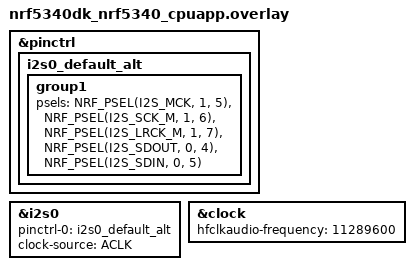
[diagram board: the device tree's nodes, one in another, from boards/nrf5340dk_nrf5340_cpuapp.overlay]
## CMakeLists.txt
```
cmake_minimum_required(VERSION 3.20.0)
find_package(Zephyr REQUIRED HINTS $ENV{ZEPHYR_BASE})

project(i2s_rx_tx)

target_sources(app PRIVATE 
    src/main.c
    src/i2s_txrx.c
    src/ble_drv.c
)

zephyr_library_include_directories(
  src/
)
```

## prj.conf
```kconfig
### Logger module
CONFIG_LOG=y
CONFIG_UART_CONSOLE=y

### RTOS settings

# Zephyr peripheral drivers
CONFIG_GPIO=y
CONFIG_I2S=y
CONFIG_I2S_NRFX=y

### BLE settings

# Enable nrf BLE
# DEFAULT SETTINGS
# Broadcast support (BT_BROADCASTER) is enabled.
# The SoftDevice Controller is used (BT_LL_CHOICE = BT_LL_SOFTDEVICE).
# The TX Power is set to 0 dBm (BT_CTLR_TX_PWR = BT_CTLR_TX_PWR_0)
CONFIG_BT=y
CONFIG_BT_PERIPHERAL=y
CONFIG_BT_DEVICE_NAME="WMic"

# Increase stack size for the main thread and System Workqueue
CONFIG_SYSTEM_WORKQUEUE_STACK_SIZE=2048
CONFIG_MAIN_STACK_SIZE=2048
```

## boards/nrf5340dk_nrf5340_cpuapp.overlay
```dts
/ {
};

&pinctrl {
	i2s0_default_alt: i2s0_default_alt {
		group1 {
			psels = <NRF_PSEL(I2S_MCK, 1, 5)>,
					<NRF_PSEL(I2S_SCK_M, 1, 6)>,
			        <NRF_PSEL(I2S_LRCK_M, 1, 7)>,
			        <NRF_PSEL(I2S_SDOUT, 0, 4)>,
			        <NRF_PSEL(I2S_SDIN, 0, 5)>;
		};
	};
};

&i2s0 {
	status = "okay";
	pinctrl-0 = <&i2s0_default_alt>;
	pinctrl-names = "default";
	clock-source = "ACLK";
};

&clock {
	hfclkaudio-frequency = <11289600>;
};
```

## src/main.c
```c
/* System */
#include <zephyr/kernel.h>
#include <zephyr/devicetree.h>
#include <zephyr/device.h>
#include <zephyr/drivers/gpio.h>
/* Standard C libraries */
#include <stdio.h>
/* Debug support */
#include <zephyr/sys/printk.h>

#include "i2s_txrx.h"
#include "ble_drv.h"

#define I2S_DEBUG 0

/* LED data structures */
const struct gpio_dt_spec led = GPIO_DT_SPEC_GET(DT_NODELABEL(led1), gpios);

/* I2S data structures */
const struct device *i2s_dev = DEVICE_DT_GET(DT_NODELABEL(i2s0));
i2s_drv_config_t hi2s;
static struct i2s_config i2s_cfg_local = {0};

static int i2s_rxtx_init(void);
static int start_transfer(i2s_drv_config_t *hi2s);
static int continue_transfer(i2s_drv_config_t *hi2s);

static int led_init(void);

K_MEM_SLAB_DEFINE(rxtx_mem_slab, BLOCK_SIZE, NUM_BLOCKS, 4);

int main(void)
{
    /* LED init */
    led_init();

    /* I2S init */
    i2s_rxtx_init();

    /* BLE init */
    ble_init();

    k_sleep(K_MSEC(500));

    /* Start peripheral advertising */
    ble_start_adv();

    /* Signal advertising is started */
    gpio_pin_set(led.port, led.pin, 1);

    /* Start the transmission */
    start_transfer(&hi2s); // I2S peripheral needs at least 2 blocks ready before the trigger start

    /* Trigger start*/
    i2s_trigger_txrx(&hi2s);

    /* Bare metal settings
     *
     *  NOTE1; these settings are not possible with
     *        Zephyr APIs.
     *
     *  NOTE2; these settings must be set after i2s_trigger_txrx() to have effect.
     */
    NRF_I2S0->CONFIG.MCKFREQ = 0x6B20F000; // Calculated via script octave
    NRF_I2S0->CONFIG.RATIO = 7;            // 384 (stick to octave calculations)

    while (1)
    {
        /* RX and TX continuosly */
        continue_transfer(&hi2s);
    }
    return 0;
}

/**
 * @brief i2s_rxtx_init
 *
 * @return int
 */
static int i2s_rxtx_init(void)
{
    /* Check device is ready */
    if (!device_is_ready(i2s_dev))
    {
        printf("I2S device not ready\n");
        return -1;
    }

    /* Configure I2S */
    hi2s.dev_i2s = i2s_dev;
    hi2s.i2s_cfg_dir = I2S_DIR_BOTH;
    hi2s.i2s_cfg = &i2s_cfg_local;

    i2s_cfg_local.word_size = I2S_WORD_BYTES * 8;
    i2s_cfg_local.channels = CHANNELS_NUMBER;
    i2s_cfg_local.format = I2S_FMT_DATA_FORMAT_I2S;
    i2s_cfg_local.frame_clk_freq = SAMPLE_FREQ;
    i2s_cfg_local.block_size = BLOCK_SIZE;
    i2s_cfg_local.timeout = I2S_RX_DELAY; // This is the max read delay before the i2s_read fails
    i2s_cfg_local.options = I2S_OPT_FRAME_CLK_MASTER | I2S_OPT_BIT_CLK_MASTER;
    i2s_cfg_local.mem_slab = &rxtx_mem_slab;

    return i2s_config(&hi2s);
}

/**
 * @brief start_transfer; at least 2 blocks must be allocated before triggering the start
 *
 * @param hi2s
 * @return int
 */
static int start_transfer(i2s_drv_config_t *hi2s)
{
    for (int i = 0; i < INITIAL_BLOCKS; ++i)
    {
        void *mem_block;

        if (k_mem_slab_alloc(&rxtx_mem_slab, &mem_block, K_NO_WAIT) < 0)
        {
            printk("Failed to allocate block\n");
            return -1;
        }

        memset(mem_block, 1, BLOCK_SIZE);

        if (i2s_write(hi2s->dev_i2s, mem_block, BLOCK_SIZE) < 0)
        {
            printk("Failed to write block\n");
            return -1;
        }
    }
    printk("Streams started\n");
    return 1;
}

/**
 * @brief continue_transfer
 *
 * @param hi2s
 * @return int
 */
static int continue_transfer(i2s_drv_config_t *hi2s)
{
    i2s_drv_txrx(hi2s);
#if (I2S_DEBUG == 1)
    int free_blocks = k_mem_slab_num_free_get(&rxtx_mem_slab);
    printk("Blocchi slab disponibili: %d\n", free_blocks);
#endif
    return 1;
}

/**
 * @brief led_init
 * 
 * @return int 
 */
int led_init(void)
{
    if(!gpio_is_ready_dt(&led))
    {
        return 0;
    }

    gpio_pin_configure_dt(&led, GPIO_OUTPUT_ACTIVE);

    return 1;
}
```

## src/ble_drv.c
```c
/**
 * @file ble_drv.c
 * @brief BLE advertising and connection management for Zephyr-based devices
 *
 * This module provides initialization, advertising, and connection lifecycle management
 * for Bluetooth Low Energy (BLE) peripherals using the Zephyr RTOS.
 * It enables the device to broadcast its presence with custom service UUIDs and device name,
 * and handles automatic restart of advertising after disconnection.
 *
 * Main features:
 * - Initializes the BLE stack and creates a random static address
 * - Advertises with custom flags, device name, and custom 128-bit service UUID
 * - Registers connection callbacks to manage advertising after disconnect
 * - Uses Zephyr workqueue for asynchronous advertising control
 *
 * Functions:
 * - ble_init(): Initializes the Bluetooth LE stack and prepares advertising
 * - ble_start_adv(): Starts advertising as a connectable BLE device
 *
 * Dependencies:
 * - Zephyr kernel and Bluetooth stack
 * - Logging module for runtime diagnostics
 *
 * Usage:
 * Call ble_init() once during system startup, then use ble_start_adv()
 * to begin advertising. Advertising automatically restarts after a connection is closed.
 *
 * @note
 * By default, every BLE device exposes two standard services defined by the Bluetooth SIG:
 * - Generic Access (UUID 0x1800): Handles basic device information and connection parameters.
 * - Generic Attribute (UUID 0x1801): Manages GATT database operations.
 * These services are always present and automatically added by the BLE
 */

#include "ble_drv.h"

#include <zephyr/kernel.h>
#include <zephyr/logging/log.h>
/* Include the header file of the Bluetooth LE stack */
#include <zephyr/bluetooth/bluetooth.h> // BLE stack
#include <zephyr/bluetooth/gap.h>       // BLE GAP layer
#include <zephyr/bluetooth/uuid.h>      // BLE UUIDs
#include <zephyr/bluetooth/addr.h>      // BLE address types
#include <zephyr/bluetooth/conn.h>      // BLE connection

LOG_MODULE_REGISTER(ble_logs, LOG_LEVEL_INF);

#define DEVICE_NAME CONFIG_BT_DEVICE_NAME
#define DEVICE_NAME_LEN (sizeof(DEVICE_NAME) - 1)

/**
 * @brief work element
 *
 */
static struct k_work adv_work;

/**
 * @brief Bluetooth connection element
 */
struct bt_conn *my_conn = NULL;

/**
 * @brief Advertising data
 *
 * @note in BT_DATA_BYTES after type, each entry is a single byte
 * @note only 31 octects available
 */
static const struct bt_data ad[] = {
    /* Set the advertising flags */
    BT_DATA_BYTES(BT_DATA_FLAGS, (BT_LE_AD_GENERAL | BT_LE_AD_NO_BREDR)), // BT_LE_AD_GENERAL enable the discoverable mode
    /* Set the advertising packet data */
    BT_DATA(BT_DATA_NAME_COMPLETE, DEVICE_NAME, DEVICE_NAME_LEN),
};

/**
 * @brief scan response data
 *
 */
static const struct bt_data sd[] = {
    /* Set the UUID (identifies the service) */
    BT_DATA_BYTES(
        BT_DATA_UUID128_ALL,
        0x12, 0x34, 0x56, 0x78, 0x9a, 0xbc, 0xde, 0xf0,
        0x12, 0x34, 0x56, 0x78, 0x9a, 0xbc, 0xde, 0xf0), // Custum service UUID
};

static void adv_work_handler(struct k_work *work);
static void advertising_start(void);
static void recycled_cb(void);
static void on_connected_cb(struct bt_conn *conn, uint8_t err);
static void on_disconnected_cb(struct bt_conn *conn, uint8_t reason);

/**
 * @brief assign callback functions to bluetooth events
 *
 */
BT_CONN_CB_DEFINE(conn_callbacks) = {
    .connected = on_connected_cb,       // post bt connection callback
    .disconnected = on_disconnected_cb, // post bt disconnection callback
    .recycled = recycled_cb,            // post bt disconnection callback
};

/**
 * @brief ble_init
 *
 * @return int
 */
int ble_init(void)
{
    bt_addr_le_t addr;
    int err;

    /* Create random static address */

    err = bt_addr_le_from_str("FF:EE:DD:CC:BB:AA", "random", &addr);
    if (err)
    {
        printk("Invalid BT address (err %d)\n", err);
        return -1;
    }

    err = bt_id_create(&addr, NULL);
    if (err < 0)
    {
        printk("Creating new ID failed (err %d)\n", err);
        return -1;
    }

    LOG_INF("Bluetooth initialized\n");

    /* Initialize adv work element */

    k_work_init(&adv_work, adv_work_handler);

    /* Enable the BLE stack */

    err = bt_enable(NULL); // Blocking mode (no callback passed)
    if (err)
    {
        LOG_ERR("Bluetooth init failed (err %d)\n", err);
        return -1;
    }

    return 1;
}

/**
 * @brief ble_start_adv
 *
 */
void ble_start_adv(void)
{
    /* Start advertising */

    advertising_start();

    return;
}

/**
 * @brief advertising_start
 *
 */
static void advertising_start(void)
{
    k_work_submit(&adv_work);
}

/**
 * @brief restart advertising after disconnection
 *
 * @param work
 */
static void adv_work_handler(struct k_work *work)
{
    int err = bt_le_adv_start(BT_LE_ADV_CONN_FAST_1, ad, ARRAY_SIZE(ad), sd, ARRAY_SIZE(sd)); // Connectable (BT_LE_ADV_CONN_FAST_1), no scan response sent (sd = NULL)
    if (err)
    {
        LOG_ERR("Advertising failed to start (err %d)\n", err);
        return;
    }
}

/**
 * @brief recycled_cb
 *
 */
static void recycled_cb(void)
{
    LOG_INF("Connection object available from previous conn. Disconnect is complete!\n");
    advertising_start();
}

/**
 * @brief on_connected_cb
 */
static void on_connected_cb(struct bt_conn *conn, uint8_t err)
{
    if (err)
    {
        LOG_ERR("Connection error %d", err);
        return;
    }
    LOG_INF("Connected");
    my_conn = bt_conn_ref(conn);
}

/**
 * @brief on_disconnected_cb
 */
static void on_disconnected_cb(struct bt_conn *conn, uint8_t reason)
{
    LOG_INF("Disconnected. Reason %d", reason);
    bt_conn_unref(my_conn);
}
```

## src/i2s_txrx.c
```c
/* System */
#include <zephyr/device.h>
/* Standard C libraries */
#include <stdio.h>
/* Debug support */
#include <zephyr/sys/printk.h>

#include "i2s_txrx.h"

/**
 * @brief i2s_config
 *
 * @return int
 */
int i2s_config(i2s_drv_config_t *hi2s)
{
    if (i2s_configure(hi2s->dev_i2s, hi2s->i2s_cfg_dir, hi2s->i2s_cfg) < 0)
    {
        printf("Failed to configure I2S\n");
        return -1;
    }
    return 0;
}

/**
 * @brief i2s_drv_write
 *
 * @return int
 */
int i2s_drv_txrx(i2s_drv_config_t *hi2s)
{
    void *mem_block;
    uint32_t block_size;

    if (i2s_read(hi2s->dev_i2s, &mem_block, &block_size) < 0)
        return -1;

    int32_t *pmem = (int32_t *)mem_block;
    int size = block_size / sizeof(int32_t);

    for (int i = 0; i < size; i++)
    {
        if ((pmem[i] <= MAX_LIMIT) && (pmem[i] >= MIN_LIMIT))
        {
            pmem[i] <<= AMP_FACTOR;
        }
        else
        {
            pmem[i] = (pmem[i] >= 0) ? INT32_MAX : INT32_MIN;
        }
    }

    if (i2s_write(hi2s->dev_i2s, mem_block, block_size) < 0)
        return -1;

    return 0;
}

/**
 * @brief i2s_trigger_txrx
 *
 * @param hi2s
 * @return int
 */
int i2s_trigger_txrx(i2s_drv_config_t *hi2s)
{
    if (i2s_trigger(hi2s->dev_i2s, I2S_DIR_BOTH, I2S_TRIGGER_START) < 0)
    {
        printf("Could not trigger TX I2S\n");
        return -1;
    }
    return 0;
}
```

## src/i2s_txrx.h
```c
#ifndef I2S_RXTX
#define I2S_RXTX

/* System */
#include <zephyr/kernel.h>
#include <zephyr/drivers/i2s.h>

/* Support */
#include <math.h>
#include <limits.h>

/* Audio defines */
#define AMP_FACTOR 3
#define MAX_LIMIT (INT32_MAX / (pow(2, AMP_FACTOR)))
#define MIN_LIMIT (INT32_MIN / (pow(2, AMP_FACTOR)))

/* I2S defines */
#define CHANNELS_NUMBER 2
#define SAMPLE_FREQ 20000  // Calculated via script octave
#define I2S_WORD_BYTES 4  // 32 bits word
#define I2S_RX_DELAY 2000 // After this time, i2s_read and i2s_write gives an error

/* Buffer defines */
#define BUFFER_BLOCK_TIME_MS 200
#define DATA_BUFFER_SIZE (SAMPLE_FREQ * BUFFER_BLOCK_TIME_MS / 1000)
#define INITIAL_BLOCKS 2
#define AVAILABLE_BLOCKS 5
#define NUM_BLOCKS (INITIAL_BLOCKS + AVAILABLE_BLOCKS)
#define BLOCK_SIZE (CHANNELS_NUMBER * DATA_BUFFER_SIZE * I2S_WORD_BYTES)

typedef struct
{
    const struct device *dev_i2s;
    struct i2s_config *i2s_cfg;
    uint8_t i2s_cfg_dir;
} i2s_drv_config_t;

int i2s_config(i2s_drv_config_t *hi2s);
int i2s_drv_txrx(i2s_drv_config_t *hi2s);
int i2s_trigger_txrx(i2s_drv_config_t *hi2s);

#endif /* I2S_RXTX */
```
